# ESP32-P4 register map
Vendor: ESPRESSIF SYSTEMS (SHANGHAI) CO., LTD.; Series: ESP32 P-Series; File version: 3
CPU: RV32IMAFC r0p0, little endian, no MPU, FPU, 0 interrupt priority bits
Address unit: 32 bits
Registers are 32-bit, read-write, reset 0x0 unless marked. A register's access mark holds for its fields unless they carry their own. Offsets are from the block's base; [hi:lo] are bit positions; {n}, {i} and the like mark numbered series.

## HP_SYS_CLKRST — HP_SYS_CLKRST Peripheral
Base 0x500E6000
0x00 CLK_EN0 reset 0x1 — Reserved
  [0] REG_CLK_EN
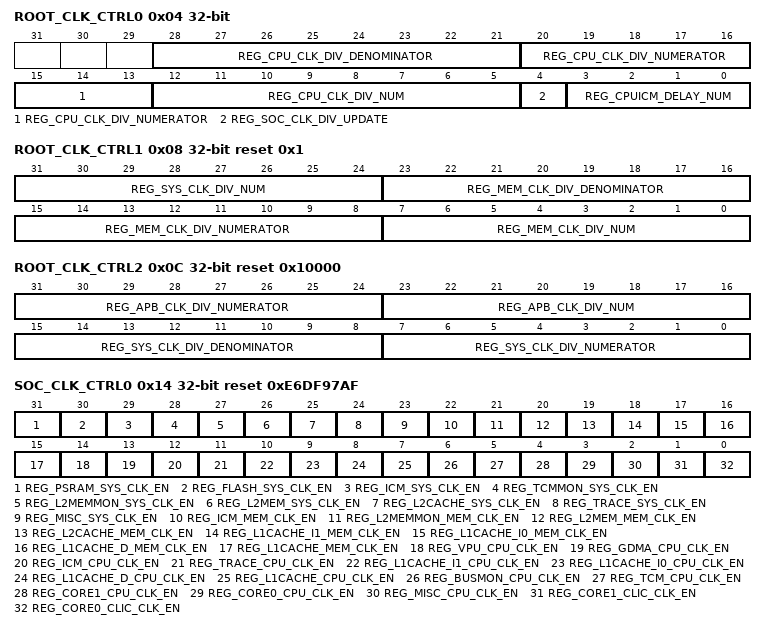
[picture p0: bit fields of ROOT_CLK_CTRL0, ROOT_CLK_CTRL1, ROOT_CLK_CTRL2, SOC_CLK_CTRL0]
0x04 ROOT_CLK_CTRL0 access per field — Reserved
  [28:21] REG_CPU_CLK_DIV_DENOMINATOR rw — Reserved
  [20:13] REG_CPU_CLK_DIV_NUMERATOR rw — Reserved
  [12:5] REG_CPU_CLK_DIV_NUM rw — Reserved
  [4] REG_SOC_CLK_DIV_UPDATE wo — Reserved
  [3:0] REG_CPUICM_DELAY_NUM rw — Reserved
0x08 ROOT_CLK_CTRL1 reset 0x1 — Reserved
  [31:24] REG_SYS_CLK_DIV_NUM — Reserved
  [23:16] REG_MEM_CLK_DIV_DENOMINATOR — Reserved
  [15:8] REG_MEM_CLK_DIV_NUMERATOR — Reserved
  [7:0] REG_MEM_CLK_DIV_NUM — Reserved
0x0C ROOT_CLK_CTRL2 reset 0x10000 — Reserved
  [31:24] REG_APB_CLK_DIV_NUMERATOR — Reserved
  [23:16] REG_APB_CLK_DIV_NUM — Reserved
  [15:8] REG_SYS_CLK_DIV_DENOMINATOR — Reserved
  [7:0] REG_SYS_CLK_DIV_NUMERATOR — Reserved
0x10 ROOT_CLK_CTRL3 — Reserved
  [7:0] REG_APB_CLK_DIV_DENOMINATOR
0x14 SOC_CLK_CTRL0 reset 0xE6DF97AF — Reserved
  [31] REG_PSRAM_SYS_CLK_EN — Reserved
  [30] REG_FLASH_SYS_CLK_EN — Reserved
  [29] REG_ICM_SYS_CLK_EN — Reserved
  [28] REG_TCMMON_SYS_CLK_EN — Reserved
  [27] REG_L2MEMMON_SYS_CLK_EN — Reserved
  [26] REG_L2MEM_SYS_CLK_EN — Reserved
  [25] REG_L2CACHE_SYS_CLK_EN — Reserved
  [24] REG_TRACE_SYS_CLK_EN — Reserved
  [23] REG_MISC_SYS_CLK_EN — Reserved
  [22] REG_ICM_MEM_CLK_EN — Reserved
  [21] REG_L2MEMMON_MEM_CLK_EN — Reserved
  [20] REG_L2MEM_MEM_CLK_EN — Reserved
  [19] REG_L2CACHE_MEM_CLK_EN — Reserved
  [18] REG_L1CACHE_I1_MEM_CLK_EN — Reserved
  [17] REG_L1CACHE_I0_MEM_CLK_EN — Reserved
  [16] REG_L1CACHE_D_MEM_CLK_EN — Reserved
  [15] REG_L1CACHE_MEM_CLK_EN — Reserved
  [14] REG_VPU_CPU_CLK_EN — Reserved
  [13] REG_GDMA_CPU_CLK_EN — Reserved
  [12] REG_ICM_CPU_CLK_EN — Reserved
  [11] REG_TRACE_CPU_CLK_EN — Reserved
  [10] REG_L1CACHE_I1_CPU_CLK_EN — Reserved
  [9] REG_L1CACHE_I0_CPU_CLK_EN — Reserved
  [8] REG_L1CACHE_D_CPU_CLK_EN — Reserved
  [7] REG_L1CACHE_CPU_CLK_EN — Reserved
  [6] REG_BUSMON_CPU_CLK_EN — Reserved
  [5] REG_TCM_CPU_CLK_EN — Reserved
  [4] REG_CORE1_CPU_CLK_EN — Reserved
  [3] REG_CORE0_CPU_CLK_EN — Reserved
  [2] REG_MISC_CPU_CLK_EN — Reserved
  [1] REG_CORE1_CLIC_CLK_EN — Reserved
  [0] REG_CORE0_CLIC_CLK_EN — Reserved
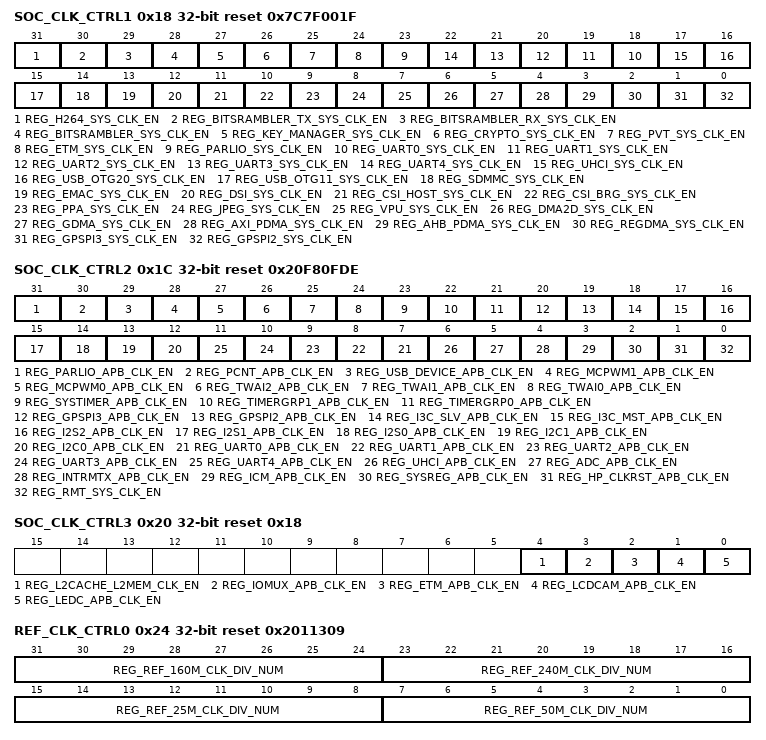
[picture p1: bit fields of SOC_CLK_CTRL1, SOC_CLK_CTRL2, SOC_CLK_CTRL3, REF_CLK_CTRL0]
0x18 SOC_CLK_CTRL1 reset 0x7C7F001F — Reserved
  [31] REG_H264_SYS_CLK_EN — Reserved
  [30] REG_BITSRAMBLER_TX_SYS_CLK_EN — Reserved
  [29] REG_BITSRAMBLER_RX_SYS_CLK_EN — Reserved
  [28] REG_BITSRAMBLER_SYS_CLK_EN — Reserved
  [27] REG_KEY_MANAGER_SYS_CLK_EN — Reserved
  [26] REG_CRYPTO_SYS_CLK_EN — Reserved
  [25] REG_PVT_SYS_CLK_EN — Reserved
  [24] REG_ETM_SYS_CLK_EN — Reserved
  [23] REG_PARLIO_SYS_CLK_EN — Reserved
  [n+18] REG_UART{n}_SYS_CLK_EN (n=0..4) — Reserved
  [17] REG_UHCI_SYS_CLK_EN — Reserved
  [16] REG_USB_OTG20_SYS_CLK_EN — Reserved
  [15] REG_USB_OTG11_SYS_CLK_EN — Reserved
  [14] REG_SDMMC_SYS_CLK_EN — Reserved
  [13] REG_EMAC_SYS_CLK_EN — Reserved
  [12] REG_DSI_SYS_CLK_EN — Reserved
  [11] REG_CSI_HOST_SYS_CLK_EN — Reserved
  [10] REG_CSI_BRG_SYS_CLK_EN — Reserved
  [9] REG_PPA_SYS_CLK_EN — Reserved
  [8] REG_JPEG_SYS_CLK_EN — Reserved
  [7] REG_VPU_SYS_CLK_EN — Reserved
  [6] REG_DMA2D_SYS_CLK_EN — Reserved
  [5] REG_GDMA_SYS_CLK_EN — Reserved
  [4] REG_AXI_PDMA_SYS_CLK_EN — Reserved
  [3] REG_AHB_PDMA_SYS_CLK_EN — Reserved
  [2] REG_REGDMA_SYS_CLK_EN — Reserved
  [1] REG_GPSPI3_SYS_CLK_EN — Reserved
  [0] REG_GPSPI2_SYS_CLK_EN — Reserved
0x1C SOC_CLK_CTRL2 reset 0x20F80FDE — Reserved
  [31] REG_PARLIO_APB_CLK_EN — Reserved
  [30] REG_PCNT_APB_CLK_EN — Reserved
  [29] REG_USB_DEVICE_APB_CLK_EN — Reserved
  [28] REG_MCPWM1_APB_CLK_EN — Reserved
  [27] REG_MCPWM0_APB_CLK_EN — Reserved
  [26] REG_TWAI2_APB_CLK_EN — Reserved
  [25] REG_TWAI1_APB_CLK_EN — Reserved
  [24] REG_TWAI0_APB_CLK_EN — Reserved
  [23] REG_SYSTIMER_APB_CLK_EN — Reserved
  [22] REG_TIMERGRP1_APB_CLK_EN — Reserved
  [21] REG_TIMERGRP0_APB_CLK_EN — Reserved
  [20] REG_GPSPI3_APB_CLK_EN — Reserved
  [19] REG_GPSPI2_APB_CLK_EN — Reserved
  [18] REG_I3C_SLV_APB_CLK_EN — Reserved
  [17] REG_I3C_MST_APB_CLK_EN — Reserved
  [16] REG_I2S2_APB_CLK_EN — Reserved
  [15] REG_I2S1_APB_CLK_EN — Reserved
  [14] REG_I2S0_APB_CLK_EN — Reserved
  [13] REG_I2C1_APB_CLK_EN — Reserved
  [12] REG_I2C0_APB_CLK_EN — Reserved
  [n+7] REG_UART{n}_APB_CLK_EN (n=0..4) — Reserved
  [6] REG_UHCI_APB_CLK_EN — Reserved
  [5] REG_ADC_APB_CLK_EN — Reserved
  [4] REG_INTRMTX_APB_CLK_EN — Reserved
  [3] REG_ICM_APB_CLK_EN — Reserved
  [2] REG_SYSREG_APB_CLK_EN — Reserved
  [1] REG_HP_CLKRST_APB_CLK_EN — Reserved
  [0] REG_RMT_SYS_CLK_EN — Reserved
0x20 SOC_CLK_CTRL3 reset 0x18 — Reserved
  [4] REG_L2CACHE_L2MEM_CLK_EN — Reserved
  [3] REG_IOMUX_APB_CLK_EN — Reserved
  [2] REG_ETM_APB_CLK_EN — Reserved
  [1] REG_LCDCAM_APB_CLK_EN — Reserved
  [0] REG_LEDC_APB_CLK_EN — Reserved
0x24 REF_CLK_CTRL0 reset 0x2011309 — Reserved
  [31:24] REG_REF_160M_CLK_DIV_NUM — Reserved
  [23:16] REG_REF_240M_CLK_DIV_NUM — Reserved
  [15:8] REG_REF_25M_CLK_DIV_NUM — Reserved
  [7:0] REG_REF_50M_CLK_DIV_NUM — Reserved
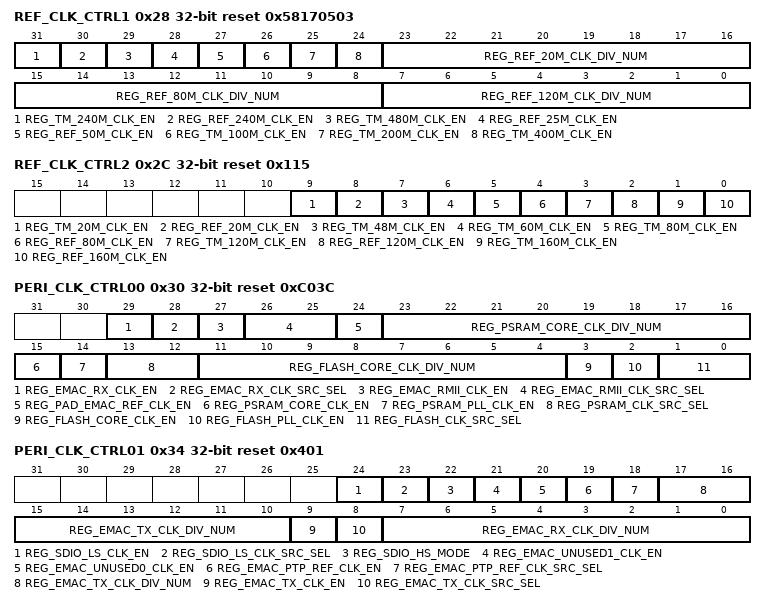
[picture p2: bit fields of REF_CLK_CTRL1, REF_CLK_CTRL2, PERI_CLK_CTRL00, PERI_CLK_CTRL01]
0x28 REF_CLK_CTRL1 reset 0x58170503 — Reserved
  [31] REG_TM_240M_CLK_EN — Reserved
  [30] REG_REF_240M_CLK_EN — Reserved
  [29] REG_TM_480M_CLK_EN — Reserved
  [28] REG_REF_25M_CLK_EN — Reserved
  [27] REG_REF_50M_CLK_EN — Reserved
  [26] REG_TM_100M_CLK_EN — Reserved
  [25] REG_TM_200M_CLK_EN — Reserved
  [24] REG_TM_400M_CLK_EN — Reserved
  [23:16] REG_REF_20M_CLK_DIV_NUM — Reserved
  [15:8] REG_REF_80M_CLK_DIV_NUM — Reserved
  [7:0] REG_REF_120M_CLK_DIV_NUM — Reserved
0x2C REF_CLK_CTRL2 reset 0x115 — Reserved
  [9] REG_TM_20M_CLK_EN — Reserved
  [8] REG_REF_20M_CLK_EN — Reserved
  [7] REG_TM_48M_CLK_EN — Reserved
  [6] REG_TM_60M_CLK_EN — Reserved
  [5] REG_TM_80M_CLK_EN — Reserved
  [4] REG_REF_80M_CLK_EN — Reserved
  [3] REG_TM_120M_CLK_EN — Reserved
  [2] REG_REF_120M_CLK_EN — Reserved
  [1] REG_TM_160M_CLK_EN — Reserved
  [0] REG_REF_160M_CLK_EN — Reserved
0x30 PERI_CLK_CTRL00 reset 0xC03C — Reserved
  [29] REG_EMAC_RX_CLK_EN — Reserved
  [28] REG_EMAC_RX_CLK_SRC_SEL — Reserved
  [27] REG_EMAC_RMII_CLK_EN — Reserved
  [26:25] REG_EMAC_RMII_CLK_SRC_SEL — Reserved
  [24] REG_PAD_EMAC_REF_CLK_EN — Reserved
  [23:16] REG_PSRAM_CORE_CLK_DIV_NUM — Reserved
  [15] REG_PSRAM_CORE_CLK_EN — Reserved
  [14] REG_PSRAM_PLL_CLK_EN — Reserved
  [13:12] REG_PSRAM_CLK_SRC_SEL — Reserved
  [11:4] REG_FLASH_CORE_CLK_DIV_NUM — Reserved
  [3] REG_FLASH_CORE_CLK_EN — Reserved
  [2] REG_FLASH_PLL_CLK_EN — Reserved
  [1:0] REG_FLASH_CLK_SRC_SEL — Reserved
0x34 PERI_CLK_CTRL01 reset 0x401 — Reserved
  [24] REG_SDIO_LS_CLK_EN — Reserved
  [23] REG_SDIO_LS_CLK_SRC_SEL — Reserved
  [22] REG_SDIO_HS_MODE — Reserved
  [21] REG_EMAC_UNUSED1_CLK_EN — Reserved
  [20] REG_EMAC_UNUSED0_CLK_EN — Reserved
  [19] REG_EMAC_PTP_REF_CLK_EN — Reserved
  [18] REG_EMAC_PTP_REF_CLK_SRC_SEL — Reserved
  [17:10] REG_EMAC_TX_CLK_DIV_NUM — Reserved
  [9] REG_EMAC_TX_CLK_EN — Reserved
  [8] REG_EMAC_TX_CLK_SRC_SEL — Reserved
  [7:0] REG_EMAC_RX_CLK_DIV_NUM — Reserved
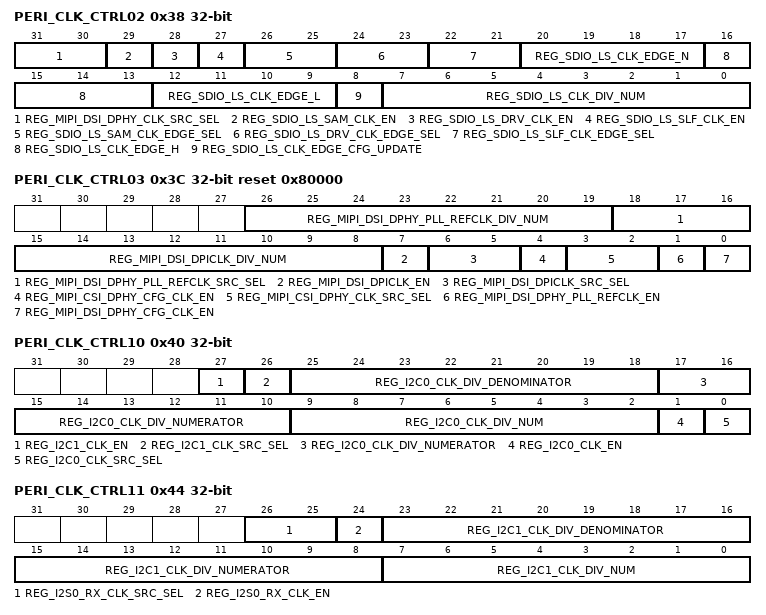
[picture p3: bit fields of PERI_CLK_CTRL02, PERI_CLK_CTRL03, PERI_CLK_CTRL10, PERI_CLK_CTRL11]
0x38 PERI_CLK_CTRL02 access per field — Reserved
  [31:30] REG_MIPI_DSI_DPHY_CLK_SRC_SEL rw — Reserved
  [29] REG_SDIO_LS_SAM_CLK_EN rw — Reserved
  [28] REG_SDIO_LS_DRV_CLK_EN rw — Reserved
  [27] REG_SDIO_LS_SLF_CLK_EN rw — Reserved
  [26:25] REG_SDIO_LS_SAM_CLK_EDGE_SEL rw — Reserved
  [24:23] REG_SDIO_LS_DRV_CLK_EDGE_SEL rw — Reserved
  [22:21] REG_SDIO_LS_SLF_CLK_EDGE_SEL rw — Reserved
  [20:17] REG_SDIO_LS_CLK_EDGE_N rw — Reserved
  [16:13] REG_SDIO_LS_CLK_EDGE_H rw — Reserved
  [12:9] REG_SDIO_LS_CLK_EDGE_L rw — Reserved
  [8] REG_SDIO_LS_CLK_EDGE_CFG_UPDATE wo — Reserved
  [7:0] REG_SDIO_LS_CLK_DIV_NUM rw — Reserved
0x3C PERI_CLK_CTRL03 reset 0x80000 — Reserved
  [26:19] REG_MIPI_DSI_DPHY_PLL_REFCLK_DIV_NUM — Reserved
  [18:16] REG_MIPI_DSI_DPHY_PLL_REFCLK_SRC_SEL — Reserved
  [15:8] REG_MIPI_DSI_DPICLK_DIV_NUM — Reserved
  [7] REG_MIPI_DSI_DPICLK_EN — Reserved
  [6:5] REG_MIPI_DSI_DPICLK_SRC_SEL — Reserved
  [4] REG_MIPI_CSI_DPHY_CFG_CLK_EN — Reserved
  [3:2] REG_MIPI_CSI_DPHY_CLK_SRC_SEL — Reserved
  [1] REG_MIPI_DSI_DPHY_PLL_REFCLK_EN — Reserved
  [0] REG_MIPI_DSI_DPHY_CFG_CLK_EN — Reserved
0x40 PERI_CLK_CTRL10 — Reserved
  [27] REG_I2C1_CLK_EN — Reserved
  [26] REG_I2C1_CLK_SRC_SEL — Reserved
  [25:18] REG_I2C0_CLK_DIV_DENOMINATOR — Reserved
  [17:10] REG_I2C0_CLK_DIV_NUMERATOR — Reserved
  [9:2] REG_I2C0_CLK_DIV_NUM — Reserved
  [1] REG_I2C0_CLK_EN — Reserved
  [0] REG_I2C0_CLK_SRC_SEL — Reserved
0x44 PERI_CLK_CTRL11 — Reserved
  [26:25] REG_I2S0_RX_CLK_SRC_SEL — Reserved
  [24] REG_I2S0_RX_CLK_EN — Reserved
  [23:16] REG_I2C1_CLK_DIV_DENOMINATOR — Reserved
  [15:8] REG_I2C1_CLK_DIV_NUMERATOR — Reserved
  [7:0] REG_I2C1_CLK_DIV_NUM — Reserved
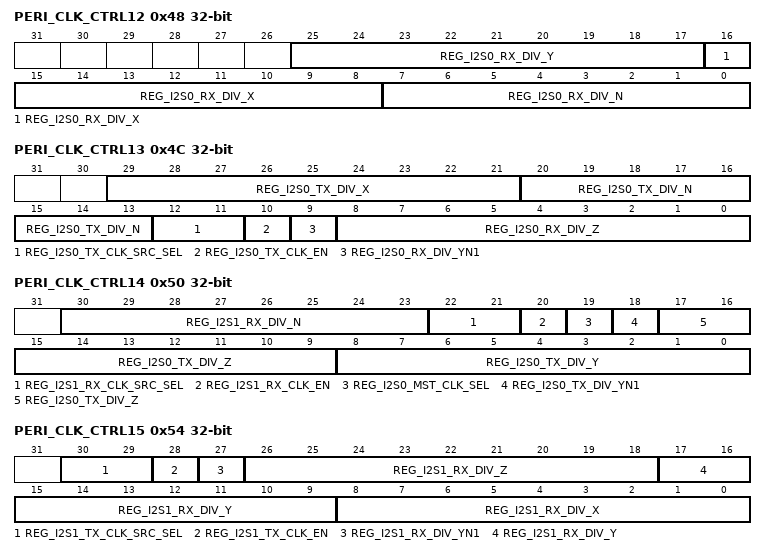
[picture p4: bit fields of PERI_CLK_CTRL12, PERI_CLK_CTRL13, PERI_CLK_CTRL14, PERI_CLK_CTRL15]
0x48 PERI_CLK_CTRL12 — Reserved
  [25:17] REG_I2S0_RX_DIV_Y — Reserved
  [16:8] REG_I2S0_RX_DIV_X — Reserved
  [7:0] REG_I2S0_RX_DIV_N — Reserved
0x4C PERI_CLK_CTRL13 — Reserved
  [29:21] REG_I2S0_TX_DIV_X — Reserved
  [20:13] REG_I2S0_TX_DIV_N — Reserved
  [12:11] REG_I2S0_TX_CLK_SRC_SEL — Reserved
  [10] REG_I2S0_TX_CLK_EN — Reserved
  [9] REG_I2S0_RX_DIV_YN1 — Reserved
  [8:0] REG_I2S0_RX_DIV_Z — Reserved
0x50 PERI_CLK_CTRL14 — Reserved
  [30:23] REG_I2S1_RX_DIV_N — Reserved
  [22:21] REG_I2S1_RX_CLK_SRC_SEL — Reserved
  [20] REG_I2S1_RX_CLK_EN — Reserved
  [19] REG_I2S0_MST_CLK_SEL — Reserved
  [18] REG_I2S0_TX_DIV_YN1 — Reserved
  [17:9] REG_I2S0_TX_DIV_Z — Reserved
  [8:0] REG_I2S0_TX_DIV_Y — Reserved
0x54 PERI_CLK_CTRL15 — Reserved
  [30:29] REG_I2S1_TX_CLK_SRC_SEL — Reserved
  [28] REG_I2S1_TX_CLK_EN — Reserved
  [27] REG_I2S1_RX_DIV_YN1 — Reserved
  [26:18] REG_I2S1_RX_DIV_Z — Reserved
  [17:9] REG_I2S1_RX_DIV_Y — Reserved
  [8:0] REG_I2S1_RX_DIV_X — Reserved
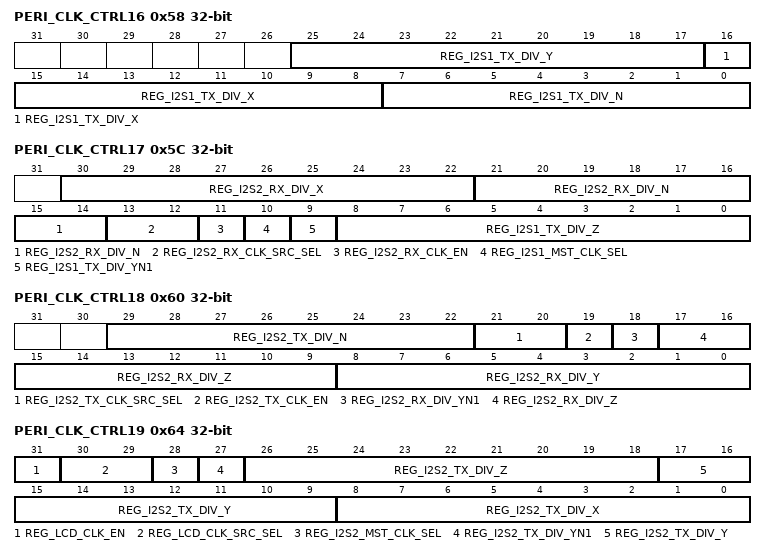
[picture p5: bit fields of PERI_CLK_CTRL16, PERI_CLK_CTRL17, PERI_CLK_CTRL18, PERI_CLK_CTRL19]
0x58 PERI_CLK_CTRL16 — Reserved
  [25:17] REG_I2S1_TX_DIV_Y — Reserved
  [16:8] REG_I2S1_TX_DIV_X — Reserved
  [7:0] REG_I2S1_TX_DIV_N — Reserved
0x5C PERI_CLK_CTRL17 — Reserved
  [30:22] REG_I2S2_RX_DIV_X — Reserved
  [21:14] REG_I2S2_RX_DIV_N — Reserved
  [13:12] REG_I2S2_RX_CLK_SRC_SEL — Reserved
  [11] REG_I2S2_RX_CLK_EN — Reserved
  [10] REG_I2S1_MST_CLK_SEL — Reserved
  [9] REG_I2S1_TX_DIV_YN1 — Reserved
  [8:0] REG_I2S1_TX_DIV_Z — Reserved
0x60 PERI_CLK_CTRL18 — Reserved
  [29:22] REG_I2S2_TX_DIV_N — Reserved
  [21:20] REG_I2S2_TX_CLK_SRC_SEL — Reserved
  [19] REG_I2S2_TX_CLK_EN — Reserved
  [18] REG_I2S2_RX_DIV_YN1 — Reserved
  [17:9] REG_I2S2_RX_DIV_Z — Reserved
  [8:0] REG_I2S2_RX_DIV_Y — Reserved
0x64 PERI_CLK_CTRL19 — Reserved
  [31] REG_LCD_CLK_EN — Reserved
  [30:29] REG_LCD_CLK_SRC_SEL — Reserved
  [28] REG_I2S2_MST_CLK_SEL — Reserved
  [27] REG_I2S2_TX_DIV_YN1 — Reserved
  [26:18] REG_I2S2_TX_DIV_Z — Reserved
  [17:9] REG_I2S2_TX_DIV_Y — Reserved
  [8:0] REG_I2S2_TX_DIV_X — Reserved
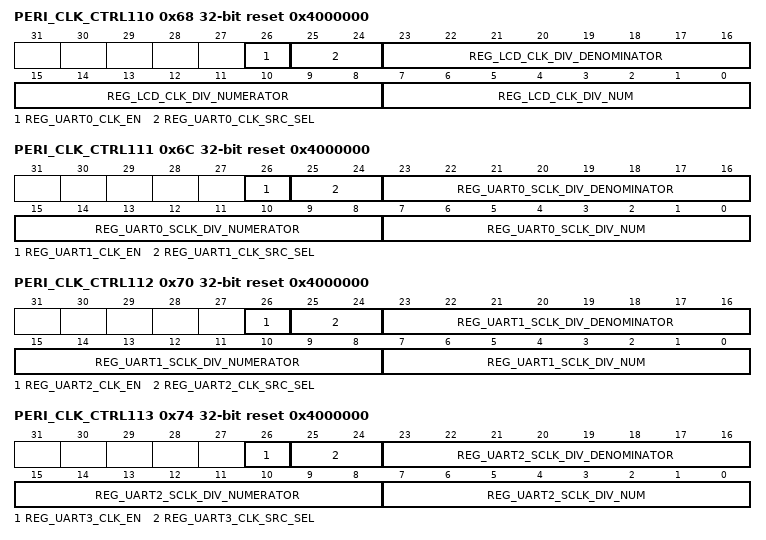
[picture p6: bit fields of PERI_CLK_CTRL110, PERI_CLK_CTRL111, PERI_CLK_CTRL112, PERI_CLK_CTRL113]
0x68 PERI_CLK_CTRL110 reset 0x4000000 — Reserved
  [26] REG_UART0_CLK_EN — Reserved
  [25:24] REG_UART0_CLK_SRC_SEL — Reserved
  [23:16] REG_LCD_CLK_DIV_DENOMINATOR — Reserved
  [15:8] REG_LCD_CLK_DIV_NUMERATOR — Reserved
  [7:0] REG_LCD_CLK_DIV_NUM — Reserved
0x6C PERI_CLK_CTRL111 reset 0x4000000 — Reserved
  [26] REG_UART1_CLK_EN — Reserved
  [25:24] REG_UART1_CLK_SRC_SEL — Reserved
  [23:16] REG_UART0_SCLK_DIV_DENOMINATOR — Reserved
  [15:8] REG_UART0_SCLK_DIV_NUMERATOR — Reserved
  [7:0] REG_UART0_SCLK_DIV_NUM — Reserved
0x70 PERI_CLK_CTRL112 reset 0x4000000 — Reserved
  [26] REG_UART2_CLK_EN — Reserved
  [25:24] REG_UART2_CLK_SRC_SEL — Reserved
  [23:16] REG_UART1_SCLK_DIV_DENOMINATOR — Reserved
  [15:8] REG_UART1_SCLK_DIV_NUMERATOR — Reserved
  [7:0] REG_UART1_SCLK_DIV_NUM — Reserved
0x74 PERI_CLK_CTRL113 reset 0x4000000 — Reserved
  [26] REG_UART3_CLK_EN — Reserved
  [25:24] REG_UART3_CLK_SRC_SEL — Reserved
  [23:16] REG_UART2_SCLK_DIV_DENOMINATOR — Reserved
  [15:8] REG_UART2_SCLK_DIV_NUMERATOR — Reserved
  [7:0] REG_UART2_SCLK_DIV_NUM — Reserved
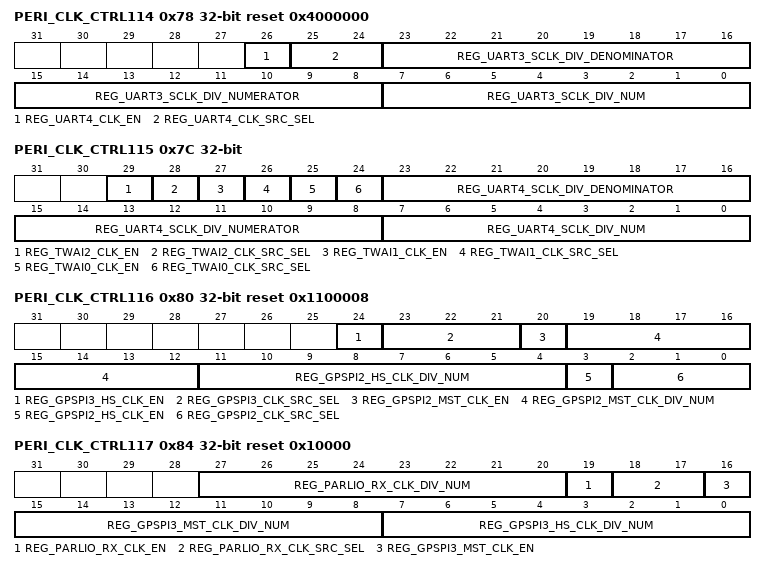
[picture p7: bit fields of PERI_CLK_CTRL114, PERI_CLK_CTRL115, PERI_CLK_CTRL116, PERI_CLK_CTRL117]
0x78 PERI_CLK_CTRL114 reset 0x4000000 — Reserved
  [26] REG_UART4_CLK_EN — Reserved
  [25:24] REG_UART4_CLK_SRC_SEL — Reserved
  [23:16] REG_UART3_SCLK_DIV_DENOMINATOR — Reserved
  [15:8] REG_UART3_SCLK_DIV_NUMERATOR — Reserved
  [7:0] REG_UART3_SCLK_DIV_NUM — Reserved
0x7C PERI_CLK_CTRL115 — Reserved
  [29] REG_TWAI2_CLK_EN — Reserved
  [28] REG_TWAI2_CLK_SRC_SEL — Reserved
  [27] REG_TWAI1_CLK_EN — Reserved
  [26] REG_TWAI1_CLK_SRC_SEL — Reserved
  [25] REG_TWAI0_CLK_EN — Reserved
  [24] REG_TWAI0_CLK_SRC_SEL — Reserved
  [23:16] REG_UART4_SCLK_DIV_DENOMINATOR — Reserved
  [15:8] REG_UART4_SCLK_DIV_NUMERATOR — Reserved
  [7:0] REG_UART4_SCLK_DIV_NUM — Reserved
0x80 PERI_CLK_CTRL116 reset 0x1100008 — Reserved
  [24] REG_GPSPI3_HS_CLK_EN — Reserved
  [23:21] REG_GPSPI3_CLK_SRC_SEL — Reserved
  [20] REG_GPSPI2_MST_CLK_EN — Reserved
  [19:12] REG_GPSPI2_MST_CLK_DIV_NUM — Reserved
  [11:4] REG_GPSPI2_HS_CLK_DIV_NUM — Reserved
  [3] REG_GPSPI2_HS_CLK_EN — Reserved
  [2:0] REG_GPSPI2_CLK_SRC_SEL — Reserved
0x84 PERI_CLK_CTRL117 reset 0x10000 — Reserved
  [27:20] REG_PARLIO_RX_CLK_DIV_NUM — Reserved
  [19] REG_PARLIO_RX_CLK_EN — Reserved
  [18:17] REG_PARLIO_RX_CLK_SRC_SEL — Reserved
  [16] REG_GPSPI3_MST_CLK_EN — Reserved
  [15:8] REG_GPSPI3_MST_CLK_DIV_NUM — Reserved
  [7:0] REG_GPSPI3_HS_CLK_DIV_NUM — Reserved
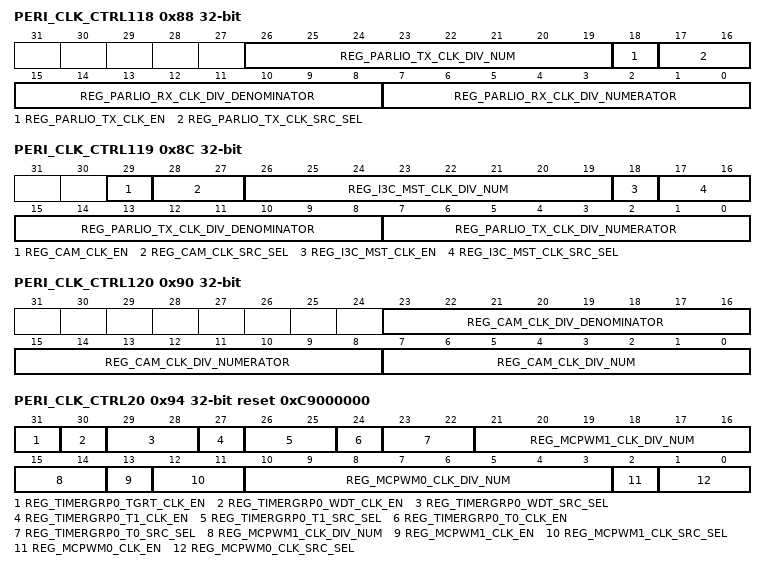
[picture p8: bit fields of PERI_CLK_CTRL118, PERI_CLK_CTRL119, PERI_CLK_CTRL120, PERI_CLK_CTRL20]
0x88 PERI_CLK_CTRL118 — Reserved
  [26:19] REG_PARLIO_TX_CLK_DIV_NUM — Reserved
  [18] REG_PARLIO_TX_CLK_EN — Reserved
  [17:16] REG_PARLIO_TX_CLK_SRC_SEL — Reserved
  [15:8] REG_PARLIO_RX_CLK_DIV_DENOMINATOR — Reserved
  [7:0] REG_PARLIO_RX_CLK_DIV_NUMERATOR — Reserved
0x8C PERI_CLK_CTRL119 — Reserved
  [29] REG_CAM_CLK_EN — Reserved
  [28:27] REG_CAM_CLK_SRC_SEL — Reserved
  [26:19] REG_I3C_MST_CLK_DIV_NUM — Reserved
  [18] REG_I3C_MST_CLK_EN — Reserved
  [17:16] REG_I3C_MST_CLK_SRC_SEL — Reserved
  [15:8] REG_PARLIO_TX_CLK_DIV_DENOMINATOR — Reserved
  [7:0] REG_PARLIO_TX_CLK_DIV_NUMERATOR — Reserved
0x90 PERI_CLK_CTRL120 — Reserved
  [23:16] REG_CAM_CLK_DIV_DENOMINATOR — Reserved
  [15:8] REG_CAM_CLK_DIV_NUMERATOR — Reserved
  [7:0] REG_CAM_CLK_DIV_NUM — Reserved
0x94 PERI_CLK_CTRL20 reset 0xC9000000 — Reserved
  [31] REG_TIMERGRP0_TGRT_CLK_EN — Reserved
  [30] REG_TIMERGRP0_WDT_CLK_EN — Reserved
  [29:28] REG_TIMERGRP0_WDT_SRC_SEL — Reserved
  [27] REG_TIMERGRP0_T1_CLK_EN — Reserved
  [26:25] REG_TIMERGRP0_T1_SRC_SEL — Reserved
  [24] REG_TIMERGRP0_T0_CLK_EN — Reserved
  [23:22] REG_TIMERGRP0_T0_SRC_SEL — Reserved
  [21:14] REG_MCPWM1_CLK_DIV_NUM — Reserved
  [13] REG_MCPWM1_CLK_EN — Reserved
  [12:11] REG_MCPWM1_CLK_SRC_SEL — Reserved
  [10:3] REG_MCPWM0_CLK_DIV_NUM — Reserved
  [2] REG_MCPWM0_CLK_EN — Reserved
  [1:0] REG_MCPWM0_CLK_SRC_SEL — Reserved
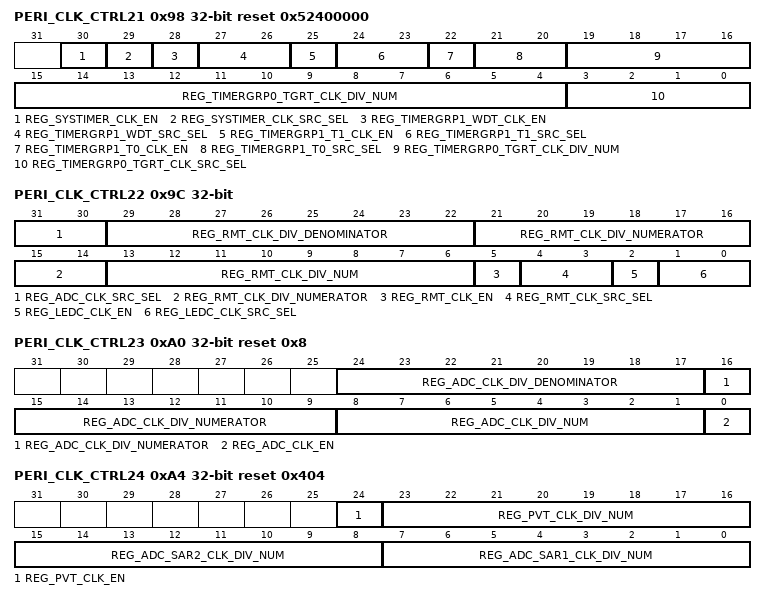
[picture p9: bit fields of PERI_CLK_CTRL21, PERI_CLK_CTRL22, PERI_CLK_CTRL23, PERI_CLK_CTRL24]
0x98 PERI_CLK_CTRL21 reset 0x52400000 — Reserved
  [30] REG_SYSTIMER_CLK_EN — Reserved
  [29] REG_SYSTIMER_CLK_SRC_SEL — Reserved
  [28] REG_TIMERGRP1_WDT_CLK_EN — Reserved
  [27:26] REG_TIMERGRP1_WDT_SRC_SEL — Reserved
  [25] REG_TIMERGRP1_T1_CLK_EN — Reserved
  [24:23] REG_TIMERGRP1_T1_SRC_SEL — Reserved
  [22] REG_TIMERGRP1_T0_CLK_EN — Reserved
  [21:20] REG_TIMERGRP1_T0_SRC_SEL — Reserved
  [19:4] REG_TIMERGRP0_TGRT_CLK_DIV_NUM — Reserved
  [3:0] REG_TIMERGRP0_TGRT_CLK_SRC_SEL — Reserved
0x9C PERI_CLK_CTRL22 — Reserved
  [31:30] REG_ADC_CLK_SRC_SEL — Reserved
  [29:22] REG_RMT_CLK_DIV_DENOMINATOR — Reserved
  [21:14] REG_RMT_CLK_DIV_NUMERATOR — Reserved
  [13:6] REG_RMT_CLK_DIV_NUM — Reserved
  [5] REG_RMT_CLK_EN — Reserved
  [4:3] REG_RMT_CLK_SRC_SEL — Reserved
  [2] REG_LEDC_CLK_EN — Reserved
  [1:0] REG_LEDC_CLK_SRC_SEL — Reserved
0xA0 PERI_CLK_CTRL23 reset 0x8 — Reserved
  [24:17] REG_ADC_CLK_DIV_DENOMINATOR — Reserved
  [16:9] REG_ADC_CLK_DIV_NUMERATOR — Reserved
  [8:1] REG_ADC_CLK_DIV_NUM — Reserved
  [0] REG_ADC_CLK_EN — Reserved
0xA4 PERI_CLK_CTRL24 reset 0x404 — Reserved
  [24] REG_PVT_CLK_EN — Reserved
  [23:16] REG_PVT_CLK_DIV_NUM — Reserved
  [15:8] REG_ADC_SAR2_CLK_DIV_NUM — Reserved
  [7:0] REG_ADC_SAR1_CLK_DIV_NUM — Reserved
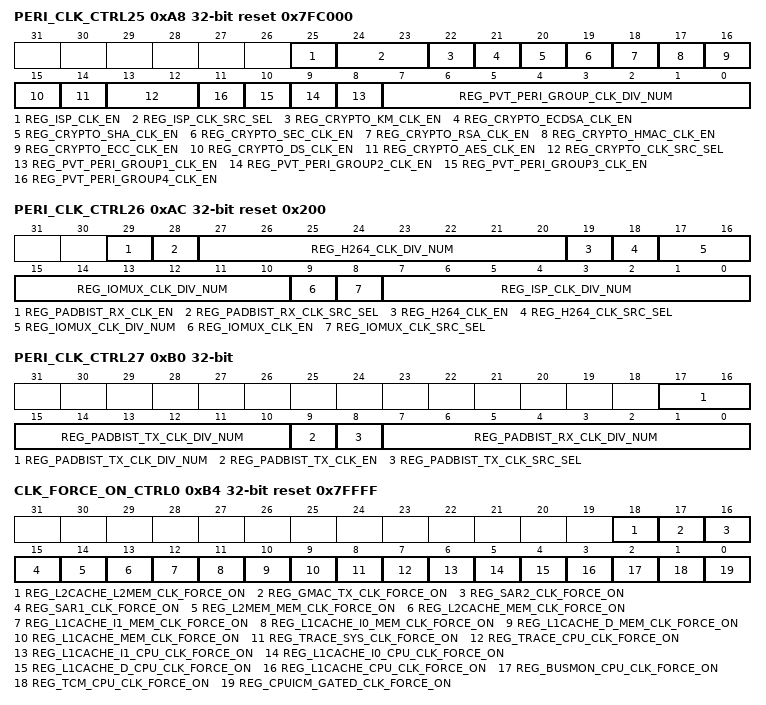
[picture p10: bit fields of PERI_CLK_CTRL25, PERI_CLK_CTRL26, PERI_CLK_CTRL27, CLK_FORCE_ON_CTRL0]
0xA8 PERI_CLK_CTRL25 reset 0x7FC000 — Reserved
  [25] REG_ISP_CLK_EN — Reserved
  [24:23] REG_ISP_CLK_SRC_SEL — Reserved
  [22] REG_CRYPTO_KM_CLK_EN — Reserved
  [21] REG_CRYPTO_ECDSA_CLK_EN — Reserved
  [20] REG_CRYPTO_SHA_CLK_EN — Reserved
  [19] REG_CRYPTO_SEC_CLK_EN — Reserved
  [18] REG_CRYPTO_RSA_CLK_EN — Reserved
  [17] REG_CRYPTO_HMAC_CLK_EN — Reserved
  [16] REG_CRYPTO_ECC_CLK_EN — Reserved
  [15] REG_CRYPTO_DS_CLK_EN — Reserved
  [14] REG_CRYPTO_AES_CLK_EN — Reserved
  [13:12] REG_CRYPTO_CLK_SRC_SEL — Reserved
  [n+7] REG_PVT_PERI_GROUP{n}_CLK_EN (n=1..4) — Reserved
  [7:0] REG_PVT_PERI_GROUP_CLK_DIV_NUM — Reserved
0xAC PERI_CLK_CTRL26 reset 0x200 — Reserved
  [29] REG_PADBIST_RX_CLK_EN — Reserved
  [28] REG_PADBIST_RX_CLK_SRC_SEL — Reserved
  [27:20] REG_H264_CLK_DIV_NUM — Reserved
  [19] REG_H264_CLK_EN — Reserved
  [18] REG_H264_CLK_SRC_SEL — Reserved
  [17:10] REG_IOMUX_CLK_DIV_NUM — Reserved
  [9] REG_IOMUX_CLK_EN — Reserved
  [8] REG_IOMUX_CLK_SRC_SEL — Reserved
  [7:0] REG_ISP_CLK_DIV_NUM — Reserved
0xB0 PERI_CLK_CTRL27 — Reserved
  [17:10] REG_PADBIST_TX_CLK_DIV_NUM — Reserved
  [9] REG_PADBIST_TX_CLK_EN — Reserved
  [8] REG_PADBIST_TX_CLK_SRC_SEL — Reserved
  [7:0] REG_PADBIST_RX_CLK_DIV_NUM — Reserved
0xB4 CLK_FORCE_ON_CTRL0 reset 0x7FFFF — Reserved
  [18] REG_L2CACHE_L2MEM_CLK_FORCE_ON — Reserved
  [17] REG_GMAC_TX_CLK_FORCE_ON — Reserved
  [16] REG_SAR2_CLK_FORCE_ON — Reserved
  [15] REG_SAR1_CLK_FORCE_ON — Reserved
  [14] REG_L2MEM_MEM_CLK_FORCE_ON — Reserved
  [13] REG_L2CACHE_MEM_CLK_FORCE_ON — Reserved
  [12] REG_L1CACHE_I1_MEM_CLK_FORCE_ON — Reserved
  [11] REG_L1CACHE_I0_MEM_CLK_FORCE_ON — Reserved
  [10] REG_L1CACHE_D_MEM_CLK_FORCE_ON — Reserved
  [9] REG_L1CACHE_MEM_CLK_FORCE_ON — Reserved
  [8] REG_TRACE_SYS_CLK_FORCE_ON — Reserved
  [7] REG_TRACE_CPU_CLK_FORCE_ON — Reserved
  [6] REG_L1CACHE_I1_CPU_CLK_FORCE_ON — Reserved
  [5] REG_L1CACHE_I0_CPU_CLK_FORCE_ON — Reserved
  [4] REG_L1CACHE_D_CPU_CLK_FORCE_ON — Reserved
  [3] REG_L1CACHE_CPU_CLK_FORCE_ON — Reserved
  [2] REG_BUSMON_CPU_CLK_FORCE_ON — Reserved
  [1] REG_TCM_CPU_CLK_FORCE_ON — Reserved
  [0] REG_CPUICM_GATED_CLK_FORCE_ON — Reserved
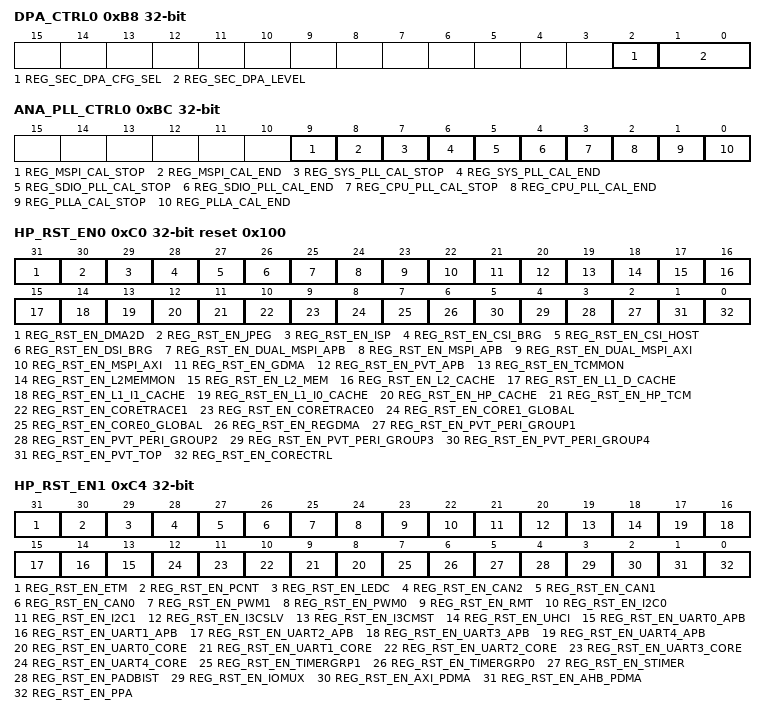
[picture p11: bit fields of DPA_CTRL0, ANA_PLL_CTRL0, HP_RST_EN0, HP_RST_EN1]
0xB8 DPA_CTRL0 — Reserved
  [2] REG_SEC_DPA_CFG_SEL — Reserved
  [1:0] REG_SEC_DPA_LEVEL — Reserved
0xBC ANA_PLL_CTRL0 access per field — Reserved
  [9] REG_MSPI_CAL_STOP rw — Reserved
  [8] REG_MSPI_CAL_END ro — Reserved
  [7] REG_SYS_PLL_CAL_STOP rw — Reserved
  [6] REG_SYS_PLL_CAL_END ro — Reserved
  [5] REG_SDIO_PLL_CAL_STOP rw — Reserved
  [4] REG_SDIO_PLL_CAL_END ro — Reserved
  [3] REG_CPU_PLL_CAL_STOP rw — Reserved
  [2] REG_CPU_PLL_CAL_END ro — Reserved
  [1] REG_PLLA_CAL_STOP rw — Reserved
  [0] REG_PLLA_CAL_END ro — Reserved
0xC0 HP_RST_EN0 reset 0x100 — Reserved
  [31] REG_RST_EN_DMA2D — Reserved
  [30] REG_RST_EN_JPEG — Reserved
  [29] REG_RST_EN_ISP — Reserved
  [28] REG_RST_EN_CSI_BRG — Reserved
  [27] REG_RST_EN_CSI_HOST — Reserved
  [26] REG_RST_EN_DSI_BRG — Reserved
  [25] REG_RST_EN_DUAL_MSPI_APB — Reserved
  [24] REG_RST_EN_MSPI_APB — Reserved
  [23] REG_RST_EN_DUAL_MSPI_AXI — Reserved
  [22] REG_RST_EN_MSPI_AXI — Reserved
  [21] REG_RST_EN_GDMA — Reserved
  [20] REG_RST_EN_PVT_APB — Reserved
  [19] REG_RST_EN_TCMMON — Reserved
  [18] REG_RST_EN_L2MEMMON — Reserved
  [17] REG_RST_EN_L2_MEM — Reserved
  [16] REG_RST_EN_L2_CACHE — Reserved
  [15] REG_RST_EN_L1_D_CACHE — Reserved
  [14] REG_RST_EN_L1_I1_CACHE — Reserved
  [13] REG_RST_EN_L1_I0_CACHE — Reserved
  [12] REG_RST_EN_HP_CACHE — Reserved
  [11] REG_RST_EN_HP_TCM — Reserved
  [10] REG_RST_EN_CORETRACE1 — Reserved
  [9] REG_RST_EN_CORETRACE0 — Reserved
  [8] REG_RST_EN_CORE1_GLOBAL — Reserved
  [7] REG_RST_EN_CORE0_GLOBAL — Reserved
  [6] REG_RST_EN_REGDMA — Reserved
  [n+1] REG_RST_EN_PVT_PERI_GROUP{n} (n=1..4) — Reserved
  [1] REG_RST_EN_PVT_TOP — Reserved
  [0] REG_RST_EN_CORECTRL — Reserved
0xC4 HP_RST_EN1 — Reserved
  [31] REG_RST_EN_ETM — Reserved
  [30] REG_RST_EN_PCNT — Reserved
  [29] REG_RST_EN_LEDC — Reserved
  [28] REG_RST_EN_CAN2 — Reserved
  [27] REG_RST_EN_CAN1 — Reserved
  [26] REG_RST_EN_CAN0 — Reserved
  [25] REG_RST_EN_PWM1 — Reserved
  [24] REG_RST_EN_PWM0 — Reserved
  [23] REG_RST_EN_RMT — Reserved
  [22] REG_RST_EN_I2C0 — Reserved
  [21] REG_RST_EN_I2C1 — Reserved
  [20] REG_RST_EN_I3CSLV — Reserved
  [19] REG_RST_EN_I3CMST — Reserved
  [18] REG_RST_EN_UHCI — Reserved
  [n+13] REG_RST_EN_UART{n}_APB (n=0..4) — Reserved
  [n+8] REG_RST_EN_UART{n}_CORE (n=0..4) — Reserved
  [7] REG_RST_EN_TIMERGRP1 — Reserved
  [6] REG_RST_EN_TIMERGRP0 — Reserved
  [5] REG_RST_EN_STIMER — Reserved
  [4] REG_RST_EN_PADBIST — Reserved
  [3] REG_RST_EN_IOMUX — Reserved
  [2] REG_RST_EN_AXI_PDMA — Reserved
  [1] REG_RST_EN_AHB_PDMA — Reserved
  [0] REG_RST_EN_PPA — Reserved
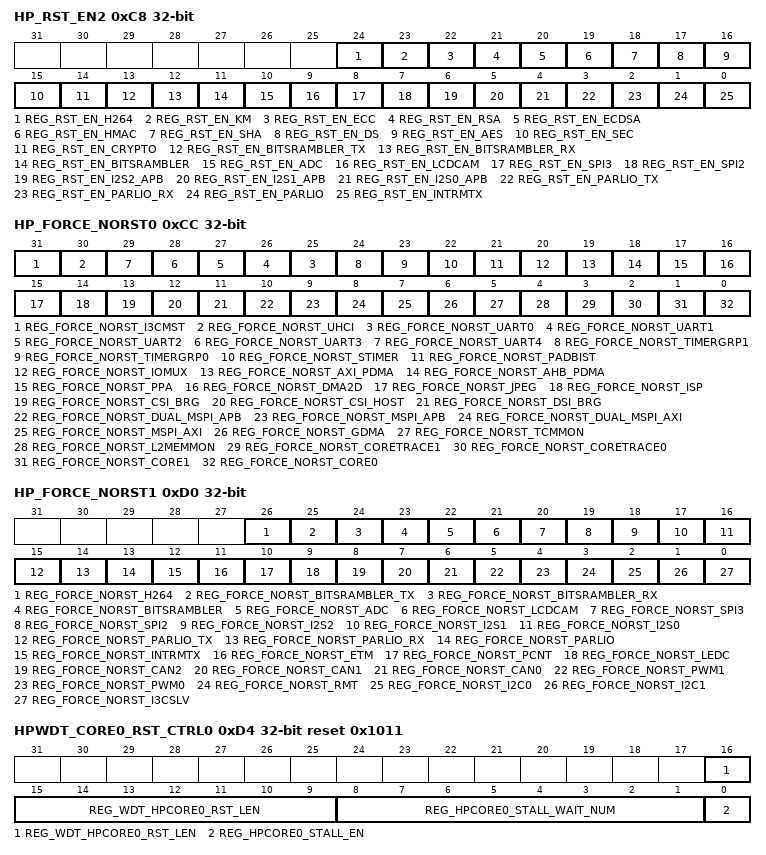
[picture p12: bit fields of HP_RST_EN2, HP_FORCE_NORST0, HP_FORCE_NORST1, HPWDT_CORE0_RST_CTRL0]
0xC8 HP_RST_EN2 — Reserved
  [24] REG_RST_EN_H264 — Reserved
  [23] REG_RST_EN_KM — Reserved
  [22] REG_RST_EN_ECC — Reserved
  [21] REG_RST_EN_RSA — Reserved
  [20] REG_RST_EN_ECDSA — Reserved
  [19] REG_RST_EN_HMAC — Reserved
  [18] REG_RST_EN_SHA — Reserved
  [17] REG_RST_EN_DS — Reserved
  [16] REG_RST_EN_AES — Reserved
  [15] REG_RST_EN_SEC — Reserved
  [14] REG_RST_EN_CRYPTO — Reserved
  [13] REG_RST_EN_BITSRAMBLER_TX — Reserved
  [12] REG_RST_EN_BITSRAMBLER_RX — Reserved
  [11] REG_RST_EN_BITSRAMBLER — Reserved
  [10] REG_RST_EN_ADC — Reserved
  [9] REG_RST_EN_LCDCAM — Reserved
  [8] REG_RST_EN_SPI3 — Reserved
  [7] REG_RST_EN_SPI2 — Reserved
  [6] REG_RST_EN_I2S2_APB — Reserved
  [5] REG_RST_EN_I2S1_APB — Reserved
  [4] REG_RST_EN_I2S0_APB — Reserved
  [3] REG_RST_EN_PARLIO_TX — Reserved
  [2] REG_RST_EN_PARLIO_RX — Reserved
  [1] REG_RST_EN_PARLIO — Reserved
  [0] REG_RST_EN_INTRMTX — Reserved
0xCC HP_FORCE_NORST0 — Reserved
  [31] REG_FORCE_NORST_I3CMST — Reserved
  [30] REG_FORCE_NORST_UHCI — Reserved
  [n+25] REG_FORCE_NORST_UART{n} (n=0..4) — Reserved
  [24] REG_FORCE_NORST_TIMERGRP1 — Reserved
  [23] REG_FORCE_NORST_TIMERGRP0 — Reserved
  [22] REG_FORCE_NORST_STIMER — Reserved
  [21] REG_FORCE_NORST_PADBIST — Reserved
  [20] REG_FORCE_NORST_IOMUX — Reserved
  [19] REG_FORCE_NORST_AXI_PDMA — Reserved
  [18] REG_FORCE_NORST_AHB_PDMA — Reserved
  [17] REG_FORCE_NORST_PPA — Reserved
  [16] REG_FORCE_NORST_DMA2D — Reserved
  [15] REG_FORCE_NORST_JPEG — Reserved
  [14] REG_FORCE_NORST_ISP — Reserved
  [13] REG_FORCE_NORST_CSI_BRG — Reserved
  [12] REG_FORCE_NORST_CSI_HOST — Reserved
  [11] REG_FORCE_NORST_DSI_BRG — Reserved
  [10] REG_FORCE_NORST_DUAL_MSPI_APB — Reserved
  [9] REG_FORCE_NORST_MSPI_APB — Reserved
  [8] REG_FORCE_NORST_DUAL_MSPI_AXI — Reserved
  [7] REG_FORCE_NORST_MSPI_AXI — Reserved
  [6] REG_FORCE_NORST_GDMA — Reserved
  [5] REG_FORCE_NORST_TCMMON — Reserved
  [4] REG_FORCE_NORST_L2MEMMON — Reserved
  [3] REG_FORCE_NORST_CORETRACE1 — Reserved
  [2] REG_FORCE_NORST_CORETRACE0 — Reserved
  [1] REG_FORCE_NORST_CORE1 — Reserved
  [0] REG_FORCE_NORST_CORE0 — Reserved
0xD0 HP_FORCE_NORST1 — Reserved
  [26] REG_FORCE_NORST_H264 — Reserved
  [25] REG_FORCE_NORST_BITSRAMBLER_TX — Reserved
  [24] REG_FORCE_NORST_BITSRAMBLER_RX — Reserved
  [23] REG_FORCE_NORST_BITSRAMBLER — Reserved
  [22] REG_FORCE_NORST_ADC — Reserved
  [21] REG_FORCE_NORST_LCDCAM — Reserved
  [20] REG_FORCE_NORST_SPI3 — Reserved
  [19] REG_FORCE_NORST_SPI2 — Reserved
  [18] REG_FORCE_NORST_I2S2 — Reserved
  [17] REG_FORCE_NORST_I2S1 — Reserved
  [16] REG_FORCE_NORST_I2S0 — Reserved
  [15] REG_FORCE_NORST_PARLIO_TX — Reserved
  [14] REG_FORCE_NORST_PARLIO_RX — Reserved
  [13] REG_FORCE_NORST_PARLIO — Reserved
  [12] REG_FORCE_NORST_INTRMTX — Reserved
  [11] REG_FORCE_NORST_ETM — Reserved
  [10] REG_FORCE_NORST_PCNT — Reserved
  [9] REG_FORCE_NORST_LEDC — Reserved
  [8] REG_FORCE_NORST_CAN2 — Reserved
  [7] REG_FORCE_NORST_CAN1 — Reserved
  [6] REG_FORCE_NORST_CAN0 — Reserved
  [5] REG_FORCE_NORST_PWM1 — Reserved
  [4] REG_FORCE_NORST_PWM0 — Reserved
  [3] REG_FORCE_NORST_RMT — Reserved
  [2] REG_FORCE_NORST_I2C0 — Reserved
  [1] REG_FORCE_NORST_I2C1 — Reserved
  [0] REG_FORCE_NORST_I3CSLV — Reserved
0xD4 HPWDT_CORE0_RST_CTRL0 reset 0x1011 — Reserved
  [16:9] REG_WDT_HPCORE0_RST_LEN — Reserved
  [8:1] REG_HPCORE0_STALL_WAIT_NUM — Reserved
  [0] REG_HPCORE0_STALL_EN — Reserved
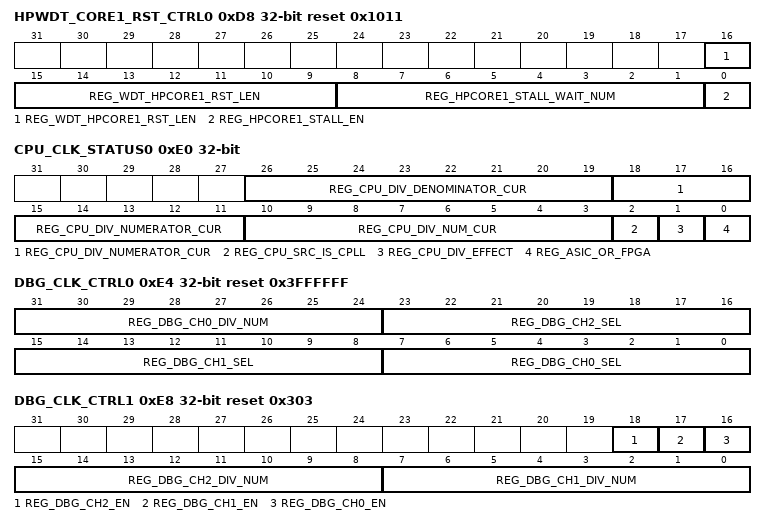
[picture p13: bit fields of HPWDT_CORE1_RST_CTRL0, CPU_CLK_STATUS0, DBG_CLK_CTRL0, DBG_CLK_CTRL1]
0xD8 HPWDT_CORE1_RST_CTRL0 reset 0x1011 — Reserved
  [16:9] REG_WDT_HPCORE1_RST_LEN — Reserved
  [8:1] REG_HPCORE1_STALL_WAIT_NUM — Reserved
  [0] REG_HPCORE1_STALL_EN — Reserved
0xDC CPU_SRC_FREQ0 ro — CPU Source Frequency
  [31:0] REG_CPU_SRC_FREQ — cpu source clock frequency, step by 0.25MHz
0xE0 CPU_CLK_STATUS0 ro — CPU Clock Status
  [26:19] REG_CPU_DIV_DENOMINATOR_CUR — cpu current div denominator
  [18:11] REG_CPU_DIV_NUMERATOR_CUR — cpu current div numerator
  [10:3] REG_CPU_DIV_NUM_CUR — cpu current div number
  [2] REG_CPU_SRC_IS_CPLL — 0: CPU source isn't cpll_400m, 1: CPU Source is cll_400m
  [1] REG_CPU_DIV_EFFECT — 0: Divider bypass, 1: Divider takes effect
  [0] REG_ASIC_OR_FPGA — 0: ASIC mode, 1: FPGA mode
0xE4 DBG_CLK_CTRL0 reset 0x3FFFFFF — Reserved
  [31:24] REG_DBG_CH0_DIV_NUM — Reserved
  [23:16] REG_DBG_CH2_SEL — Reserved
  [15:8] REG_DBG_CH1_SEL — Reserved
  [7:0] REG_DBG_CH0_SEL — Reserved
0xE8 DBG_CLK_CTRL1 reset 0x303 — Reserved
  [18] REG_DBG_CH2_EN — Reserved
  [17] REG_DBG_CH1_EN — Reserved
  [16] REG_DBG_CH0_EN — Reserved
  [15:8] REG_DBG_CH2_DIV_NUM — Reserved
  [7:0] REG_DBG_CH1_DIV_NUM — Reserved
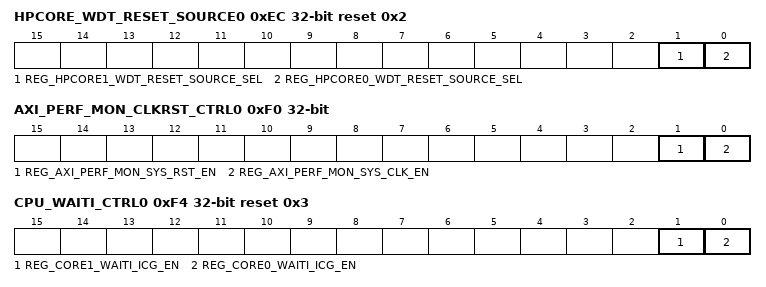
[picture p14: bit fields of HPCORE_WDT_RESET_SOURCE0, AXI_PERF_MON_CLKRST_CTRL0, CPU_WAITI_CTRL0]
0xEC HPCORE_WDT_RESET_SOURCE0 reset 0x2 — Reserved
  [1] REG_HPCORE1_WDT_RESET_SOURCE_SEL — 1'b0: use wdt0 to reset hpcore1, 1'b1: use wdt1 to reset hpcore1
  [0] REG_HPCORE0_WDT_RESET_SOURCE_SEL — 1'b0: use wdt0 to reset hpcore0, 1'b1: use wdt1 to reset hpcore0
0xF0 AXI_PERF_MON_CLKRST_CTRL0 — Reserved
  [1] REG_AXI_PERF_MON_SYS_RST_EN — Configures axi_perf_mon rst enable
  [0] REG_AXI_PERF_MON_SYS_CLK_EN — Configures axi_perf_mon clk enable
0xF4 CPU_WAITI_CTRL0 reset 0x3 — Reserved
  [1] REG_CORE1_WAITI_ICG_EN — Configures whether cpu core1 waiti signal can control clock gate. If both core0 and core1 waiti_icg_en is 1, then only when core0 and core1 all in waiti will close related clock
  [0] REG_CORE0_WAITI_ICG_EN — Configures whether cpu core0 waiti signal can control clock gate. If both core0 and core1 waiti_icg_en is 1, then only when core0 and core1 all in waiti will close related clock
